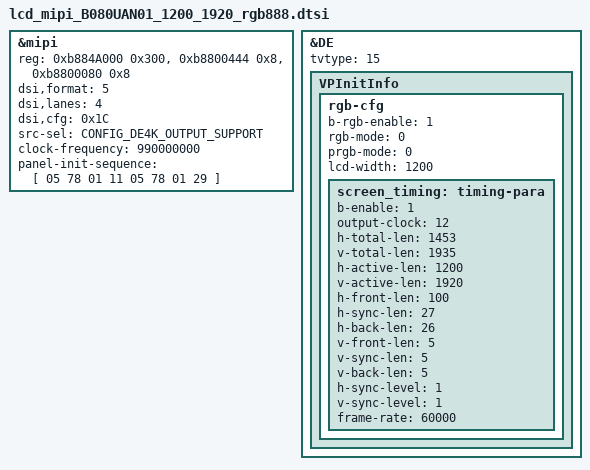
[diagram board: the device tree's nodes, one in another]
&mipi {
		reg = <0xb884A000 0x300>, <0xb8800444 0x8>,<0xb8800080 0x8>;

		/*
		 * MIPI_COLOR_RGB565_0	=	0
		 * MIPI_COLOR_RGB565_1	=	1
		 * MIPI_COLOR_RGB565_2	=	2
		 * MIPI_COLOR_RGB666_0	=	3
		 * MIPI_COLOR_RGB666_1	=	4
		 * MIPI_COLOR_RGB888	=	5
		*/
		dsi,format =<5>;

		dsi,lanes = <4>;

		/*
		 * bit 6:5 MIPI_Virtual_Channel_Generic_ID
		 * bit 4 :MIPI_CRC
		 * bit 3 :MIPI_ECC
		 * bit 2 :MIPI_Bus_Turn_request.
		 * bit 1 :MIPI_EOTp
		 * bit 0 :MIPI_EOTp
		 */
		dsi,cfg = <0x1C>;

		/*
		 * 0: E_SRC_SEL_FXDE = 0
		 * 1: E_SRC_SEL_4KDE
		 * 2: E_SRC_SEL_HDMI_RX
		 */
		src-sel = <CONFIG_DE4K_OUTPUT_SUPPORT>;
		clock-frequency = <990000000>;
		// status = "okay";
	};
&DE {
	tvtype = <15>;
	VPInitInfo {
		rgb-cfg{
			b-rgb-enable = <1>;
			/*
				* 0: MODE_PRGB
				* 1: MODE_SRGB
				*/
			rgb-mode = <0>;
			/*
				* 0: MODE_PRGB_888_10bit
				* 1: MODE_PRGB_666
				*/
			prgb-mode = <0>;
			lcd-width = <1200>;
			screen_timing: timing-para {
				/* bool type, 0 or 1*/
				b-enable = <1>;
				/*
					* VPO_RGB_CLOCK_27M = 1,
					* VPO_RGB_CLOCK_33M = 2,
					* VPO_RGB_CLOCK_49M = 3,
					* VPO_RGB_CLOCK_66M = 4,
					* VPO_RGB_CLOCK_74M = 5,
					* VPO_RGB_CLOCK_85M = 6,
					* VPO_RGB_CLOCK_108M = 7,//H1600
					* VPO_RGB_CLOCK_6_6M = 8,
					* VPO_RGB_CLOCK_9M = 9,
					* VPO_RGB_CLOCK_39_6M = 10,
					* VPO_RGB_CLOCK_74_25M = 11,//H1600
					* VPO_RGB_CLOCK_148_5M = 12,//H1600
					* VPO_RGB_CLOCK_54M = 13,//H1600
					* VPO_RGB_CLOCK_132M = 14,//H1600
				*/
				output-clock = <12>;
				h-total-len = <1453>;
				v-total-len = <1935>;

				h-active-len = <1200>;
				v-active-len = <1920>;

				h-front-len = <100>;
				h-sync-len = <27>;
				h-back-len = <26>;

				v-front-len = <5>;
				v-sync-len = <5>;
				v-back-len = <5>;
				/* bool type, 0 or 1*/
				h-sync-level = <1>;
				/* bool type, 0 or 1*/
				v-sync-level = <1>;
				frame-rate = <60000>;
			};
		};
	};
};
&mipi{
panel-init-sequence = [
	05 78 01 11
	05 78 01 29
	];
};
